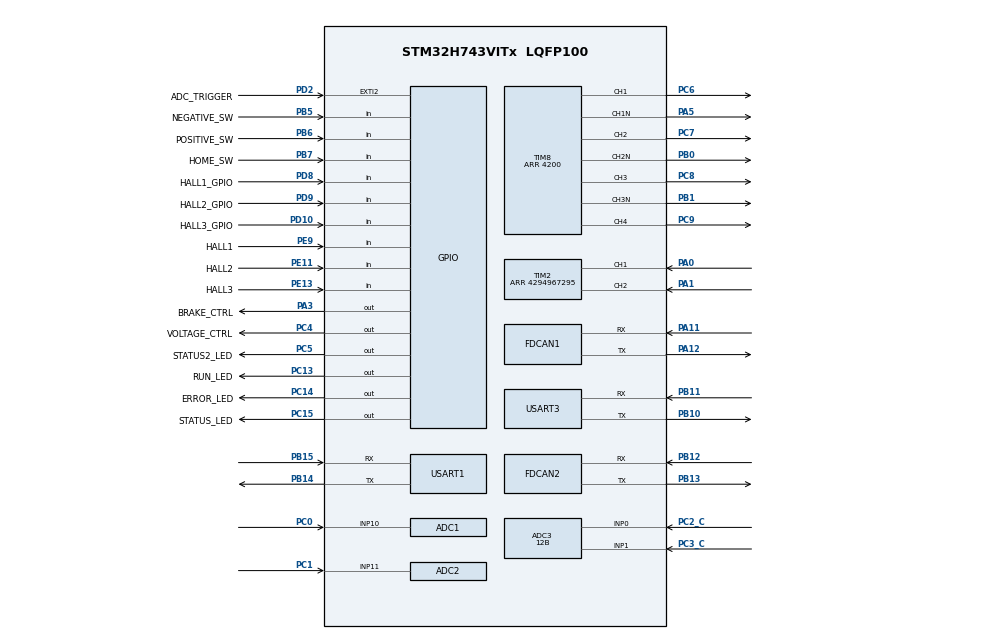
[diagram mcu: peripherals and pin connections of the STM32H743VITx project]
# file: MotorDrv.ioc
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ADC1.Channel-2\#ChannelRegularConversion=ADC_CHANNEL_10
ADC1.ClockPrescaler=ADC_CLOCK_ASYNC_DIV8
ADC1.ContinuousConvMode=DISABLE
ADC1.EOCSelection=ADC_EOC_SINGLE_CONV
ADC1.EnableRegularConversion=ENABLE
ADC1.ExternalTrigConv=ADC_EXTERNALTRIG_T8_TRGO
ADC1.ExternalTrigConvEdge=ADC_EXTERNALTRIGCONVEDGE_FALLING
ADC1.Mode=ADC_MODE_INDEPENDENT
ADC1.NbrOfConversion=1
ADC1.NbrOfConversionFlag=1
ADC1.OffsetNumber-2\#ChannelRegularConversion=ADC_OFFSET_NONE
ADC1.Rank-2\#ChannelRegularConversion=1
ADC1.Resolution=ADC_RESOLUTION_12B
ADC1.SamplingTime-2\#ChannelRegularConversion=ADC_SAMPLETIME_16CYCLES_5
ADC1.master=1
ADC2.Channel-2\#ChannelRegularConversion=ADC_CHANNEL_11
ADC2.ClockPrescaler=ADC_CLOCK_ASYNC_DIV8
ADC2.ConversionDataManagement=ADC_CONVERSIONDATA_DR
ADC2.EOCSelection=ADC_EOC_SINGLE_CONV
ADC2.ExternalTrigConv=ADC_EXTERNALTRIG_T8_TRGO
ADC2.ExternalTrigConvEdge=ADC_EXTERNALTRIGCONVEDGE_FALLING
ADC2.NbrOfConversionFlag=1
ADC2.OffsetNumber-2\#ChannelRegularConversion=ADC_OFFSET_NONE
ADC2.Rank-2\#ChannelRegularConversion=1
ADC2.Resolution=ADC_RESOLUTION_12B
ADC2.SamplingTime-2\#ChannelRegularConversion=ADC_SAMPLETIME_16CYCLES_5
ADC3.Channel-10\#ChannelRegularConversion=ADC_CHANNEL_TEMPSENSOR
ADC3.Channel-7\#ChannelRegularConversion=ADC_CHANNEL_0
ADC3.Channel-8\#ChannelRegularConversion=ADC_CHANNEL_1
ADC3.ClockPrescaler=ADC_CLOCK_ASYNC_DIV8
ADC3.ContinuousConvMode=DISABLE
ADC3.ConversionDataManagement=ADC_CONVERSIONDATA_DMA_CIRCULAR
ADC3.EOCSelection=ADC_EOC_SINGLE_CONV
ADC3.EnableRegularConversion=ENABLE
ADC3.ExternalTrigConv=ADC_EXTERNALTRIG_T8_TRGO
ADC3.ExternalTrigConvEdge=ADC_EXTERNALTRIGCONVEDGE_FALLING
ADC3.NbrOfConversion=3
ADC3.NbrOfConversionFlag=1
ADC3.OffsetNumber-10\#ChannelRegularConversion=ADC_OFFSET_NONE
ADC3.OffsetNumber-7\#ChannelRegularConversion=ADC_OFFSET_NONE
ADC3.OffsetNumber-8\#ChannelRegularConversion=ADC_OFFSET_NONE
ADC3.Overrun=ADC_OVR_DATA_PRESERVED
ADC3.Rank-10\#ChannelRegularConversion=3
ADC3.Rank-7\#ChannelRegularConversion=1
ADC3.Rank-8\#ChannelRegularConversion=2
ADC3.Resolution=ADC_RESOLUTION_12B
ADC3.SamplingTime-10\#ChannelRegularConversion=ADC_SAMPLETIME_16CYCLES_5
ADC3.SamplingTime-7\#ChannelRegularConversion=ADC_SAMPLETIME_16CYCLES_5
ADC3.SamplingTime-8\#ChannelRegularConversion=ADC_SAMPLETIME_2CYCLES_5
CORTEX_M7.CPU_DCache=Enabled
CORTEX_M7.CPU_ICache=Enabled
Dma.ADC3.2.Direction=DMA_PERIPH_TO_MEMORY
Dma.ADC3.2.EventEnable=DISABLE
Dma.ADC3.2.FIFOMode=DMA_FIFOMODE_DISABLE
Dma.ADC3.2.Instance=DMA1_Stream1
Dma.ADC3.2.MemDataAlignment=DMA_MDATAALIGN_HALFWORD
Dma.ADC3.2.MemInc=DMA_MINC_ENABLE
Dma.ADC3.2.Mode=DMA_CIRCULAR
Dma.ADC3.2.PeriphDataAlignment=DMA_PDATAALIGN_HALFWORD
Dma.ADC3.2.PeriphInc=DMA_PINC_DISABLE
Dma.ADC3.2.Polarity=HAL_DMAMUX_REQ_GEN_RISING
Dma.ADC3.2.Priority=DMA_PRIORITY_LOW
Dma.ADC3.2.RequestNumber=1
Dma.ADC3.2.SignalID=HAL_DMAMUX2_REQ_GEN_EXTI2
Dma.ADC3.2.SyncEnable=DISABLE
Dma.ADC3.2.SyncPolarity=HAL_DMAMUX_SYNC_NO_EVENT
Dma.ADC3.2.SyncRequestNumber=1
Dma.ADC3.2.SyncSignalID=NONE
Dma.Request0=USART1_RX
Dma.Request1=USART3_RX
Dma.Request2=ADC3
Dma.USART1_RX.0.Direction=DMA_PERIPH_TO_MEMORY
Dma.USART1_RX.0.EventEnable=DISABLE
Dma.USART1_RX.0.FIFOMode=DMA_FIFOMODE_ENABLE
Dma.USART1_RX.0.FIFOThreshold=DMA_FIFO_THRESHOLD_1QUARTERFULL
Dma.USART1_RX.0.Instance=DMA1_Stream2
Dma.USART1_RX.0.MemBurst=DMA_MBURST_SINGLE
Dma.USART1_RX.0.MemDataAlignment=DMA_MDATAALIGN_BYTE
Dma.USART1_RX.0.MemInc=DMA_MINC_ENABLE
Dma.USART1_RX.0.Mode=DMA_CIRCULAR
Dma.USART1_RX.0.PeriphBurst=DMA_PBURST_SINGLE
Dma.USART1_RX.0.PeriphDataAlignment=DMA_PDATAALIGN_BYTE
Dma.USART1_RX.0.PeriphInc=DMA_PINC_DISABLE
Dma.USART1_RX.0.Polarity=HAL_DMAMUX_REQ_GEN_RISING
Dma.USART1_RX.0.Priority=DMA_PRIORITY_LOW
Dma.USART1_RX.0.RequestNumber=1
Dma.USART1_RX.0.SignalID=HAL_DMAMUX1_REQ_GEN_DMAMUX1_CH1_EVT
Dma.USART1_RX.0.SyncEnable=DISABLE
Dma.USART1_RX.0.SyncPolarity=HAL_DMAMUX_SYNC_NO_EVENT
Dma.USART1_RX.0.SyncRequestNumber=1
Dma.USART1_RX.0.SyncSignalID=NONE
Dma.USART3_RX.1.Direction=DMA_PERIPH_TO_MEMORY
Dma.USART3_RX.1.EventEnable=DISABLE
Dma.USART3_RX.1.FIFOMode=DMA_FIFOMODE_ENABLE
Dma.USART3_RX.1.FIFOThreshold=DMA_FIFO_THRESHOLD_1QUARTERFULL
Dma.USART3_RX.1.Instance=DMA1_Stream0
Dma.USART3_RX.1.MemBurst=DMA_MBURST_SINGLE
Dma.USART3_RX.1.MemDataAlignment=DMA_MDATAALIGN_BYTE
Dma.USART3_RX.1.MemInc=DMA_MINC_ENABLE
Dma.USART3_RX.1.Mode=DMA_CIRCULAR
Dma.USART3_RX.1.PeriphBurst=DMA_PBURST_SINGLE
Dma.USART3_RX.1.PeriphDataAlignment=DMA_PDATAALIGN_BYTE
Dma.USART3_RX.1.PeriphInc=DMA_PINC_DISABLE
Dma.USART3_RX.1.Polarity=HAL_DMAMUX_REQ_GEN_RISING
Dma.USART3_RX.1.Priority=DMA_PRIORITY_LOW
Dma.USART3_RX.1.RequestNumber=1
Dma.USART3_RX.1.SignalID=HAL_DMAMUX1_REQ_GEN_DMAMUX1_CH2_EVT
Dma.USART3_RX.1.SyncEnable=DISABLE
Dma.USART3_RX.1.SyncPolarity=HAL_DMAMUX_SYNC_NO_EVENT
Dma.USART3_RX.1.SyncRequestNumber=1
Dma.USART3_RX.1.SyncSignalID=NONE
FDCAN1.DataPrescaler=1
FDCAN1.DataSyncJumpWidth=8
FDCAN1.DataTimeSeg1=3
FDCAN1.DataTimeSeg2=4
FDCAN1.NominalPrescaler=1
FDCAN1.NominalSyncJumpWidth=8
FDCAN1.NominalTimeSeg1=3
FDCAN1.NominalTimeSeg2=4
FDCAN1.RxBuffersNbr=0
FDCAN1.RxFifo0ElmtsNbr=1
FDCAN1.StdFiltersNbr=1
FDCAN1.TxBuffersNbr=0
FDCAN1.TxFifoQueueElmtsNbr=4
FDCAN2.DataSyncJumpWidth=4
FDCAN2.DataTimeSeg1=4
FDCAN2.DataTimeSeg2=3
FDCAN2.FrameFormat=FDCAN_FRAME_FD_BRS
FDCAN2.NominalSyncJumpWidth=8
FDCAN2.NominalTimeSeg1=39
FDCAN2.NominalTimeSeg2=8
FDCAN2.RxBufferSize=FDCAN_DATA_BYTES_64
FDCAN2.RxFifo0ElmtSize=FDCAN_DATA_BYTES_64
FDCAN2.RxFifo1ElmtSize=FDCAN_DATA_BYTES_64
FDCAN2.TxElmtSize=FDCAN_DATA_BYTES_64
Mcu.Family=STM32H7
Mcu.Name=STM32H743VITx
Mcu.Package=LQFP100
NVIC.ADC3_IRQn=true\:0\:0\:false\:false\:true\:true\:true
NVIC.ADC_IRQn=true\:0\:0\:false\:false\:true\:true\:true
NVIC.DMA1_Stream0_IRQn=true\:0\:0\:false\:false\:true\:false\:true
NVIC.DMA1_Stream1_IRQn=true\:2\:0\:true\:false\:true\:false\:true
NVIC.DMA1_Stream2_IRQn=true\:2\:0\:true\:false\:true\:false\:true
NVIC.EXTI2_IRQn=true\:0\:0\:false\:false\:true\:true\:true
NVIC.FDCAN1_IT0_IRQn=true\:2\:0\:true\:false\:true\:true\:true
NVIC.FDCAN2_IT0_IRQn=true\:2\:0\:true\:false\:true\:true\:true
NVIC.PriorityGroup=NVIC_PRIORITYGROUP_4
PA0.Signal=S_TIM2_CH1
PA1.Signal=S_TIM2_CH2
PA11.GPIO_PuPd=GPIO_PULLUP
PA11.GPIO_Speed=GPIO_SPEED_FREQ_VERY_HIGH
PA11.Mode=FDCANMaster
PA11.Signal=FDCAN1_RX
PA12.GPIO_PuPd=GPIO_PULLUP
PA12.GPIO_Speed=GPIO_SPEED_FREQ_VERY_HIGH
PA12.Mode=FDCANMaster
PA12.Signal=FDCAN1_TX
PA2.Signal=S_TIM2_CH3
PA3.GPIO_Label=BRAKE_CTRL
PA3.GPIO_ModeDefaultOutputPP=GPIO_MODE_OUTPUT_PP
PA3.GPIO_PuPd=GPIO_PULLDOWN
PA3.GPIO_Speed=GPIO_SPEED_FREQ_VERY_HIGH
PA3.PinState=GPIO_PIN_RESET
PA3.Signal=GPIO_Output
PA5.GPIO_PuPd=GPIO_PULLDOWN
PA5.GPIO_Speed=GPIO_SPEED_FREQ_VERY_HIGH
PA5.Mode=PWM Generation1 CH1 CH1N
PA5.Signal=TIM8_CH1N
PB0.GPIO_PuPd=GPIO_PULLDOWN
PB0.GPIO_Speed=GPIO_SPEED_FREQ_VERY_HIGH
PB0.Mode=PWM Generation2 CH2 CH2N
PB0.Signal=TIM8_CH2N
PB1.GPIO_PuPd=GPIO_PULLDOWN
PB1.GPIO_Speed=GPIO_SPEED_FREQ_VERY_HIGH
PB1.Mode=PWM Generation3 CH3 CH3N
PB1.Signal=TIM8_CH3N
PB10.GPIO_Speed=GPIO_SPEED_FREQ_VERY_HIGH
PB10.Mode=Asynchronous
PB10.Signal=USART3_TX
PB11.GPIO_Speed=GPIO_SPEED_FREQ_VERY_HIGH
PB11.Mode=Asynchronous
PB11.Signal=USART3_RX
PB12.GPIO_PuPd=GPIO_PULLUP
PB12.GPIO_Speed=GPIO_SPEED_FREQ_VERY_HIGH
PB12.Mode=FDCANFD
PB12.Signal=FDCAN2_RX
PB13.GPIO_PuPd=GPIO_PULLUP
PB13.GPIO_Speed=GPIO_SPEED_FREQ_VERY_HIGH
PB13.Mode=FDCANFD
PB13.Signal=FDCAN2_TX
PB14.Mode=Asynchronous
PB14.Signal=USART1_TX
PB15.Mode=Asynchronous
PB15.Signal=USART1_RX
PB5.GPIO_Label=NEGATIVE_SW
PB5.GPIO_Mode=GPIO_MODE_INPUT
PB5.GPIO_PuPd=GPIO_PULLDOWN
PB5.Signal=GPIO_Input
PB6.GPIO_Label=POSITIVE_SW
PB6.GPIO_Mode=GPIO_MODE_INPUT
PB6.GPIO_PuPd=GPIO_PULLDOWN
PB6.Signal=GPIO_Input
PB7.GPIO_Label=HOME_SW
PB7.GPIO_Mode=GPIO_MODE_INPUT
PB7.GPIO_PuPd=GPIO_PULLDOWN
PB7.Signal=GPIO_Input
PC0.Signal=ADCx_INP10
PC1.Signal=ADCx_INP11
PC13.GPIO_Label=RUN_LED
PC13.GPIO_ModeDefaultOutputPP=GPIO_MODE_OUTPUT_PP
PC13.GPIO_PuPd=GPIO_NOPULL
PC13.GPIO_Speed=GPIO_SPEED_FREQ_LOW
PC13.PinState=GPIO_PIN_RESET
PC13.Signal=GPIO_Output
PC14-OSC32_IN\ (OSC32_IN).GPIO_Label=ERROR_LED
PC14-OSC32_IN\ (OSC32_IN).GPIO_ModeDefaultOutputPP=GPIO_MODE_OUTPUT_PP
PC14-OSC32_IN\ (OSC32_IN).GPIO_PuPd=GPIO_NOPULL
PC14-OSC32_IN\ (OSC32_IN).GPIO_Speed=GPIO_SPEED_FREQ_LOW
PC14-OSC32_IN\ (OSC32_IN).PinState=GPIO_PIN_RESET
PC14-OSC32_IN\ (OSC32_IN).Signal=GPIO_Output
PC15-OSC32_OUT\ (OSC32_OUT).GPIO_Label=STATUS_LED
PC15-OSC32_OUT\ (OSC32_OUT).GPIO_ModeDefaultOutputPP=GPIO_MODE_OUTPUT_PP
PC15-OSC32_OUT\ (OSC32_OUT).GPIO_PuPd=GPIO_NOPULL
PC15-OSC32_OUT\ (OSC32_OUT).GPIO_Speed=GPIO_SPEED_FREQ_LOW
PC15-OSC32_OUT\ (OSC32_OUT).PinState=GPIO_PIN_RESET
PC15-OSC32_OUT\ (OSC32_OUT).Signal=GPIO_Output
PC2_C.Mode=IN0-Single-Ended
PC2_C.Signal=ADC3_INP0
PC3_C.Mode=IN1-Single-Ended
PC3_C.Signal=ADC3_INP1
PC4.GPIO_Label=VOLTAGE_CTRL
PC4.GPIO_ModeDefaultOutputPP=GPIO_MODE_OUTPUT_PP
PC4.GPIO_PuPd=GPIO_PULLDOWN
PC4.GPIO_Speed=GPIO_SPEED_FREQ_VERY_HIGH
PC4.PinState=GPIO_PIN_RESET
PC4.Signal=GPIO_Output
PC5.GPIO_Label=STATUS2_LED
PC5.GPIO_ModeDefaultOutputPP=GPIO_MODE_OUTPUT_PP
PC5.GPIO_PuPd=GPIO_NOPULL
PC5.GPIO_Speed=GPIO_SPEED_FREQ_LOW
PC5.PinState=GPIO_PIN_RESET
PC5.Signal=GPIO_Output
PC6.GPIO_PuPd=GPIO_PULLDOWN
PC6.GPIO_Speed=GPIO_SPEED_FREQ_VERY_HIGH
PC6.Signal=S_TIM8_CH1
PC7.GPIO_PuPd=GPIO_PULLDOWN
PC7.GPIO_Speed=GPIO_SPEED_FREQ_VERY_HIGH
PC7.Signal=S_TIM8_CH2
PC8.GPIO_PuPd=GPIO_PULLDOWN
PC8.GPIO_Speed=GPIO_SPEED_FREQ_VERY_HIGH
PC8.Signal=S_TIM8_CH3
PC9.GPIO_PuPd=GPIO_PULLDOWN
PC9.GPIO_Speed=GPIO_SPEED_FREQ_VERY_HIGH
PC9.Signal=S_TIM8_CH4
PD10.GPIO_Label=HALL3_GPIO
PD10.GPIO_Mode=GPIO_MODE_INPUT
PD10.GPIO_PuPd=GPIO_NOPULL
PD10.Signal=GPIO_Input
PD2.GPIO_Label=ADC_TRIGGER
PD2.GPIO_PuPd=GPIO_PULLDOWN
PD2.Signal=GPXTI2
PD8.GPIO_Label=HALL1_GPIO
PD8.GPIO_Mode=GPIO_MODE_INPUT
PD8.GPIO_PuPd=GPIO_NOPULL
PD8.Signal=GPIO_Input
PD9.GPIO_Label=HALL2_GPIO
PD9.GPIO_Mode=GPIO_MODE_INPUT
PD9.GPIO_PuPd=GPIO_NOPULL
PD9.Signal=GPIO_Input
PE11.GPIO_Label=HALL2
PE11.Signal=GPIO_Input
PE13.GPIO_Label=HALL3
PE13.Signal=GPIO_Input
PE9.GPIO_Label=HALL1
PE9.Signal=GPIO_Input
PH0-OSC_IN\ (PH0).Mode=HSE-External-Oscillator
PH0-OSC_IN\ (PH0).Signal=RCC_OSC_IN
PH1-OSC_OUT\ (PH1).Mode=HSE-External-Oscillator
PH1-OSC_OUT\ (PH1).Signal=RCC_OSC_OUT
ProjectManager.HeapSize=0x2000
ProjectManager.StackSize=0x2000
ProjectManager.TargetToolchain=EWARM V8
RCC.ADCCLockSelection=RCC_ADCCLKSOURCE_PLL3
RCC.ADCFreq_Value=84000000
RCC.APB1Freq_Value=84000000
RCC.APB2Freq_Value=84000000
RCC.APB3Freq_Value=84000000
RCC.APB4Freq_Value=84000000
RCC.CortexFreq_Value=168000000
RCC.D1CPRE=RCC_SYSCLK_DIV2
RCC.D1PPRE=RCC_APB3_DIV2
RCC.D2PPRE1=RCC_APB1_DIV2
RCC.D2PPRE2=RCC_APB2_DIV2
RCC.D3PPRE=RCC_APB4_DIV2
RCC.DIVM1=2
RCC.DIVM2=1
RCC.DIVM3=8
RCC.DIVN1=168
RCC.DIVN2=32
RCC.DIVN3=168
RCC.DIVP2=4
RCC.DIVQ1=4
RCC.DIVQ2=32
RCC.DIVR1=4
RCC.FDCANCLockSelection=RCC_FDCANCLKSOURCE_PLL2
RCC.HCLKFreq_Value=168000000
RCC.HSE_VALUE=8000000
RCC.PLLSourceVirtual=RCC_PLLSOURCE_HSE
RCC.PWR_Regulator_Voltage_Scale=PWR_REGULATOR_VOLTAGE_SCALE1
RCC.SYSCLKFreq_VALUE=336000000
RCC.SYSCLKSource=RCC_SYSCLKSOURCE_PLLCLK
RCC.USBFreq_Value=168000000
SH.ADCx_INP10.0=ADC1_INP10,IN10-Single-Ended
SH.ADCx_INP11.0=ADC2_INP11,IN11-Single-Ended
SH.S_TIM2_CH1.0=TIM2_CH1,Encoder_Interface
SH.S_TIM2_CH2.0=TIM2_CH2,Encoder_Interface
SH.S_TIM2_CH3.0=TIM2_CH3
SH.S_TIM8_CH1.0=TIM8_CH1,PWM Generation1 CH1 CH1N
SH.S_TIM8_CH2.0=TIM8_CH2,PWM Generation2 CH2 CH2N
SH.S_TIM8_CH3.0=TIM8_CH3,PWM Generation3 CH3 CH3N
SH.S_TIM8_CH4.0=TIM8_CH4,Output Compare4 CH4
TIM2.EncoderMode=TIM_ENCODERMODE_TI12
TIM2.Period=4294967295
TIM8.Break2State=TIM_BREAK2_DISABLE
TIM8.BreakPolarity=TIM_BREAKPOLARITY_HIGH
TIM8.BreakState=TIM_BREAK_DISABLE
TIM8.Channel-Output\ Compare4\ CH4=TIM_CHANNEL_4
TIM8.Channel-PWM\ Generation1\ CH1\ CH1N=TIM_CHANNEL_1
TIM8.Channel-PWM\ Generation2\ CH2\ CH2N=TIM_CHANNEL_2
TIM8.Channel-PWM\ Generation3\ CH3\ CH3N=TIM_CHANNEL_3
TIM8.CounterMode=TIM_COUNTERMODE_CENTERALIGNED1
TIM8.DeadTime=84
TIM8.OCMode_4=TIM_OCMODE_TOGGLE
TIM8.OCMode_PWM-PWM\ Generation1\ CH1\ CH1N=TIM_OCMODE_PWM2
TIM8.OCMode_PWM-PWM\ Generation2\ CH2\ CH2N=TIM_OCMODE_PWM2
TIM8.OCMode_PWM-PWM\ Generation3\ CH3\ CH3N=TIM_OCMODE_PWM2
TIM8.OffStateRunMode=TIM_OSSR_DISABLE
TIM8.Period=4200
TIM8.Pulse-Output\ Compare4\ CH4=4158
TIM8.Pulse-PWM\ Generation1\ CH1\ CH1N=4200
TIM8.Pulse-PWM\ Generation2\ CH2\ CH2N=4200
TIM8.Pulse-PWM\ Generation3\ CH3\ CH3N=4200
TIM8.SourceBRK2DigInput=TIM_BREAKINPUTSOURCE_DISABLE
TIM8.SourceBRKDigInput=TIM_BREAKINPUTSOURCE_DISABLE
TIM8.TIM_MasterOutputTrigger=TIM_TRGO_OC4REF
TIM8.TIM_MasterOutputTrigger2=TIM_TRGO2_OC4REF
USART1.VirtualMode-Asynchronous=VM_ASYNC
USART3.VirtualMode-Asynchronous=VM_ASYNC
VP_ADC3_TempSens_Input.Mode=IN-TempSens
VP_TIM8_VS_ClockSourceINT.Mode=Internal
board=custom

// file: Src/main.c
/* USER CODE BEGIN Header */
/**
  ******************************************************************************
  * @file           : main.c
  * @brief          : Main program body
  ******************************************************************************
  ** This notice applies to any and all portions of this file
  * that are not between comment pairs USER CODE BEGIN and
  * USER CODE END. Other portions of this file, whether
  * inserted by the user or by software development tools
  * are owned by their respective copyright owners.
  *
  * COPYRIGHT(c) 2019 STMicroelectronics
  *
  * Redistribution and use in source and binary forms, with or without modification,
  * are permitted provided that the following conditions are met:
  *   1. Redistributions of source code must retain the above copyright notice,
  *      this list of conditions and the following disclaimer.
  *   2. Redistributions in binary form must reproduce the above copyright notice,
  *      this list of conditions and the following disclaimer in the documentation
  *      and/or other materials provided with the distribution.
  *   3. Neither the name of STMicroelectronics nor the names of its contributors
  *      may be used to endorse or promote products derived from this software
  *      without specific prior written permission.
  *
  * THIS SOFTWARE IS PROVIDED BY THE COPYRIGHT HOLDERS AND CONTRIBUTORS "AS IS"
  * AND ANY EXPRESS OR IMPLIED WARRANTIES, INCLUDING, BUT NOT LIMITED TO, THE
  * IMPLIED WARRANTIES OF MERCHANTABILITY AND FITNESS FOR A PARTICULAR PURPOSE ARE
  * DISCLAIMED. IN NO EVENT SHALL THE COPYRIGHT HOLDER OR CONTRIBUTORS BE LIABLE
  * FOR ANY DIRECT, INDIRECT, INCIDENTAL, SPECIAL, EXEMPLARY, OR CONSEQUENTIAL
  * DAMAGES (INCLUDING, BUT NOT LIMITED TO, PROCUREMENT OF SUBSTITUTE GOODS OR
  * SERVICES; LOSS OF USE, DATA, OR PROFITS; OR BUSINESS INTERRUPTION) HOWEVER
  * CAUSED AND ON ANY THEORY OF LIABILITY, WHETHER IN CONTRACT, STRICT LIABILITY,
  * OR TORT (INCLUDING NEGLIGENCE OR OTHERWISE) ARISING IN ANY WAY OUT OF THE USE
  * OF THIS SOFTWARE, EVEN IF ADVISED OF THE POSSIBILITY OF SUCH DAMAGE.
  *
  ******************************************************************************
  */
/* USER CODE END Header */

#include "main.h"

/* USER CODE BEGIN Includes */
#include "ServoControllerInterface.h"
#include "string.h"
#include "can_comm.h"

/* USER CODE END Includes */

/* USER CODE BEGIN PD */
#define SERVO_FUNC_USE
#define ADC_USE_DMA
//https://community.st.com/s/article/FAQ-DMA-is-not-working-on-STM32H7-devices
#ifdef ADC_USE_DMA
#define ADC3_CHANNEL_NUM						3
#else
#define ADC3_CHANNEL_NUM						3
#endif

/* USER CODE END PD */

ADC_HandleTypeDef hadc1;
ADC_HandleTypeDef hadc2;
ADC_HandleTypeDef hadc3;
DMA_HandleTypeDef hdma_adc3;

FDCAN_HandleTypeDef hfdcan1;
FDCAN_HandleTypeDef hfdcan2;

TIM_HandleTypeDef htim2;
TIM_HandleTypeDef htim8;

UART_HandleTypeDef huart1;
UART_HandleTypeDef huart3;
DMA_HandleTypeDef hdma_usart1_rx;
DMA_HandleTypeDef hdma_usart3_rx;

/* USER CODE BEGIN PV */
//FDCAN_FilterTypeDef sFilterConfig;
FDCAN_RxHeaderTypeDef RxHeader[2];
uint8_t RxData[2][16];
FDCAN_TxHeaderTypeDef TxHeader[2];
uint8_t TxData[2][16];
//uint8_t TxData2[] = {0x10, 0x32, 0x54, 0x76, 0x98, 0x00, 0x11, 0x22, 0x33, 0x44, 0x55, 0x66, 0x77, 0x88, 0x99, 0x00};
//FDCAN_FilterTypeDef sFilterConfig;
int fifo0TxNum;

uint8_t gRunCurrentController = 0;
uint32_t nRunLed = 0;
uint16_t nRunLedCnt; //pjg++190509
uint32_t nExt2Irq = 0;
uint32_t nAdcIrq = 0;
uint32_t nAdc2Irq = 0;
uint32_t nDma2Irq = 0;

int16_t adc12Result[2];
#ifdef ADC_USE_DMA
/* Variable containing ADC conversions results */
//static int16_t   adc3Result[ADC3_CHANNEL_NUM];
uint16_t adc3Result[ADC3_CHANNEL_NUM] __attribute__((section(".ARM.__at_0x24000010")));
#else
int16_t adc3Result[ADC3_CHANNEL_NUM];
#endif
int32_t encoderPulse = 0;
volatile uint8_t hallSensorStatus = 0x00;
uint8_t encoder1Type = 0;
uint8_t encoder2Type = 0;
uint16_t nStatus2Led = 0;

/* USER CODE END PV */

void SystemClock_Config(void);
static void MX_GPIO_Init(void);
static void MX_DMA_Init(void);
static void MX_TIM8_Init(void);
static void MX_FDCAN1_Init(void);
static void MX_FDCAN2_Init(void);
static void MX_TIM2_Init(void);
static void MX_ADC1_Init(void);
static void MX_ADC2_Init(void);
static void MX_ADC3_Init(void);
static void MX_USART3_UART_Init(void);
static void MX_USART1_UART_Init(void);

/* USER CODE BEGIN 0 */
void HAL_UART_RxCpltCallback(UART_HandleTypeDef * huart)
{
	if (huart->Instance == USART1) {	//debug
		//HAL_UART_Receive_DMA(huart, (uint8_t *)&uartRxData[0], 1);
	}
	else if (huart->Instance == USART2) {	//remocon
		//CTouchDrv_PutData(uartRxData[1]);
		//HAL_UART_Receive_DMA(huart, (uint8_t *)&uartRxData[1], 1);
	}
	else if (huart->Instance == USART3) {	//WiFI
		//HAL_UART_Receive_DMA(huart, (uint8_t *)&uartRxData[2], 1);
	}
	else if (huart->Instance == USART6) {	//IMU
		//HAL_UART_Receive_DMA(huart, (uint8_t *)&uartRxData[3], 1);
	}
}

/**
  * @brief  Conversion complete callback in non-blocking mode
  * @param  hadc: ADC handle
  * @retval None
  */
void HAL_ADC_ConvCpltCallback(ADC_HandleTypeDef* hadc)
{
	//uint32_t i;
	if (hadc->Instance == ADC1 || hadc->Instance == ADC2) {
		#ifdef SERVO_FUNC_USE
		adc12Result[0] = (int16_t)HAL_ADC_GetValue(&hadc1); //U current
		adc12Result[1] = (int16_t)HAL_ADC_GetValue(&hadc2); //V current

		RunCurrentController(adc12Result[0], adc12Result[1]);

		if(++gRunCurrentController >= 10) {
			CalculateVelocity(encoderPulse);
			CalculateLoadTorque();
			RunVelocityPositionController();
			gRunCurrentController = 0;
		}
		#endif
		nAdcIrq++;
		if (nAdcIrq > nRunLedCnt)
		{
			RUN_LED_TOGGLE;
			nAdcIrq = 0;
		}
	}
	else if (hadc->Instance == ADC3) {
		#ifdef SERVO_FUNC_USE
		#ifdef ADC_USE_DMA
		#else
		adc3Result[0] = (int16_t)HAL_ADC_GetValue(&hadc3);//voltage
		adc3Result[1] = (int16_t)HAL_ADC_GetValue(&hadc3); //temp
		adc3Result[2] = (int16_t)HAL_ADC_GetValue(&hadc3); //mcu temp
		#endif
		CalculateVoltageTemperature(adc3Result[0], adc3Result[1]);
		//RUN_LED_TOGGLE;
		#endif
	}
}

/**
  * @brief  Conversion DMA half-transfer callback in non-blocking mode
  * @param  hadc: ADC handle
  * @retval None
  */
#if 0
void HAL_ADC_ConvHalfCpltCallback(ADC_HandleTypeDef* hadc)
{
	if (hadc->Instance == ADC3) {
		#ifdef SERVO_FUNC_USE
		//CalculateVoltageTemperature(adc3Result[0], adc3Result[1]);
		#endif
	}
	/* Invalidate Data Cache to get the updated content of the SRAM on the first half of the ADC converted data buffer: 32 bytes */
	//SCB_InvalidateDCache_by_Addr((uint32_t *) &aADCxConvertedData[0], ADC_CONVERTED_DATA_BUFFER_SIZE);
}
#endif

//오버런(overrun)이 발생하면 ADC 트리거를 다시 주기 위한 함수입니다.
void HAL_ADC_ErrorCallback(ADC_HandleTypeDef *hadc)
{
	//hadc->Instance->CR2 |= (uint32_t)ADC_CR2_SWSTART;
	//HAL_GPIO_TogglePin(GPIOC, STATUS2_LED_Pin);
}

 /**
  * @brief EXTI line detection callback
  * @param GPIO_Pin: Specifies the pins connected EXTI line
  * @retval None
  */
void HAL_GPIO_EXTI_Callback(uint16_t GPIO_Pin)
{
	uint8_t hallValue;

	//if (GPIO_Pin == GPIO_PIN_2)
	{
		//nExt2Irq++;
		//if (nExt2Irq > 1000) {
		//	HAL_GPIO_TogglePin(GPIOC, STATUS2_LED_Pin);
		//	nExt2Irq = 0;
		//}
		//RUN_LED_TOGGLE;
		#ifdef SERVO_FUNC_USE
		#if 1
		hallSensorStatus = 0;
		if (GPIOE->IDR & 0x200) hallSensorStatus = 0x1;
		if (GPIOE->IDR & 0x800) hallSensorStatus |= 0x2;
		if (GPIOE->IDR & 0x2000) hallSensorStatus |= 0x4;
		#else
		hallSensorStatus = (GPIOD->IDR >> 8) & 0x7;
		#endif
		encoderPulse = (int32_t)TIM2->CNT;
		CalculateElecAngle(hallSensorStatus, encoderPulse);
		#endif
	}
}

void HAL_FDCAN_RxFifo0Callback(FDCAN_HandleTypeDef *hfdcan, uint32_t RxFifo0ITs)
{
	uint32_t len;

	if((RxFifo0ITs & FDCAN_IT_RX_FIFO0_WATERMARK) != RESET)
	{
		if (hfdcan->Instance == FDCAN1) {
			/* Retreive Rx messages from RX FIFO0 */
			HAL_FDCAN_GetRxMessage(hfdcan, FDCAN_RX_FIFO0, &RxHeader[0], RxData[0]);
			#ifdef SERVO_FUNC_USE
			if(ProcessSdoCan(&RxHeader[0].Identifier, RxData[0], &len) >= 0) {
		                if (len > 8) len = 8;
				//memcpy(TxData[0], RxData[0], len);
				TxHeader[0].Identifier = RxHeader[0].Identifier;
				TxHeader[0].DataLength = (uint32_t)(len<<16);
				HAL_FDCAN_AddMessageToTxFifoQ(hfdcan, &TxHeader[0], RxData[0]);
				//if (TxData[0][1] == 0x41 && TxData[0][2] == 0x60) {
					if (nStatus2Led++ > 200) {
						nStatus2Led = 0;
						//STATUS2_LED_TOGGLE;
						HAL_GPIO_TogglePin(GPIOC, STATUS2_LED_Pin);
					}
				//}
			}
			while (Callback_MotorInfoSend(&RxHeader[0].Identifier, RxData[0], &RxHeader[0].DataLength)) { //pjg++180710
				//memcpy(TxData[0], RxData[0], len);
				TxHeader[0].Identifier = RxHeader[0].Identifier;
				TxHeader[0].DataLength = (uint32_t)(len<<16);
				HAL_FDCAN_AddMessageToTxFifoQ(hfdcan, &TxHeader[0], RxData[0]);
				if (nStatus2Led++ > 200) {
					nStatus2Led = 0;
					//STATUS2_LED_TOGGLE;
					HAL_GPIO_TogglePin(GPIOC, STATUS2_LED_Pin);
				}
			}
			#endif
			/* Activate Rx FIFO 0 watermark notification */
			HAL_FDCAN_ActivateNotification(hfdcan, FDCAN_IT_RX_FIFO0_WATERMARK, fifo0TxNum);
		}
		else if (hfdcan->Instance == FDCAN2) {
			/* Retreive Rx messages from RX FIFO0 */
			HAL_FDCAN_GetRxMessage(hfdcan, FDCAN_RX_FIFO0, &RxHeader[1], RxData[1]);
			/* Activate Rx FIFO 0 watermark notification */
			HAL_FDCAN_ActivateNotification(hfdcan, FDCAN_IT_RX_FIFO0_WATERMARK, 0);
		}
	}
}

void FDCAN1_Setting(void)
{
	int fifo0RxNum;
	FDCAN_FilterTypeDef sFilterConfig;

	fifo0RxNum = 1;
	fifo0TxNum = 0;
	/*                Bit time configuration:
	Bit time parameter         | Nominal      |  Data
	---------------------------|--------------|----------------
	fdcan_ker_ck               | 20 MHz       | 20 MHz
	Time_quantum (tq)          | 50 ns        | 50 ns
	Synchronization_segment    | 1 tq         | 1 tq
	Propagation_segment        | 23 tq        | 1 tq
	Phase_segment_1            | 8 tq         | 4 tq
	Phase_segment_2            | 8 tq         | 4 tq
	Synchronization_Jump_width | 8 tq         | 4 tq
	Bit_length                 | 40 tq = 2 탎 | 10 tq = 0.5 탎
	Bit_rate                   | 0.5 MBit/s   | 2 MBit/s
	*/
	hfdcan1.Instance = FDCAN1;
	hfdcan1.Init.FrameFormat = FDCAN_FRAME_CLASSIC;//FDCAN_FRAME_FD_BRS;
	hfdcan1.Init.Mode = FDCAN_MODE_NORMAL;
	hfdcan1.Init.AutoRetransmission = ENABLE;
	hfdcan1.Init.TransmitPause = DISABLE;
	hfdcan1.Init.ProtocolException = ENABLE;
	hfdcan1.Init.NominalPrescaler = 0x1; /* tq = NominalPrescaler x (1/fdcan_ker_ck) */
	hfdcan1.Init.NominalSyncJumpWidth = 0x8;
	hfdcan1.Init.NominalTimeSeg1 = 0x3;//1F; /* NominalTimeSeg1 = Propagation_segment + Phase_segment_1 */
	hfdcan1.Init.NominalTimeSeg2 = 0x4;//8;
	hfdcan1.Init.DataPrescaler = 0x1;//1;
	hfdcan1.Init.DataSyncJumpWidth = 0x8;//4;
	hfdcan1.Init.DataTimeSeg1 = 0x3;//1F;//5; /* DataTimeSeg1 = Propagation_segment + Phase_segment_1 */
	hfdcan1.Init.DataTimeSeg2 = 0x4;//4;
	hfdcan1.Init.MessageRAMOffset = 0;
	hfdcan1.Init.StdFiltersNbr = 1;
	hfdcan1.Init.ExtFiltersNbr = 0;
	hfdcan1.Init.RxFifo0ElmtsNbr = fifo0RxNum;
	hfdcan1.Init.RxFifo0ElmtSize = FDCAN_DATA_BYTES_8;
	hfdcan1.Init.RxFifo1ElmtsNbr = 0;
	hfdcan1.Init.RxBuffersNbr = 0;
	hfdcan1.Init.RxBufferSize = 0;//FDCAN_DATA_BYTES_8;
	hfdcan1.Init.TxEventsNbr = 0;
	hfdcan1.Init.TxBuffersNbr = fifo0TxNum;
	hfdcan1.Init.TxFifoQueueElmtsNbr = 1;
	hfdcan1.Init.TxFifoQueueMode = FDCAN_TX_FIFO_OPERATION;//FDCAN_TX_QUEUE_OPERATION;;
	hfdcan1.Init.TxElmtSize = FDCAN_DATA_BYTES_8;
	HAL_FDCAN_Init(&hfdcan1);

	/* Configure Rx filter */
	sFilterConfig.IdType = FDCAN_STANDARD_ID;
	sFilterConfig.FilterIndex = 0;
	sFilterConfig.FilterType = FDCAN_FILTER_MASK;
	sFilterConfig.FilterConfig = FDCAN_FILTER_TO_RXFIFO0;
	sFilterConfig.FilterID1 = 0;//0x111;
	sFilterConfig.FilterID2 = 0;//0x7FF; /* For acceptance, MessageID and FilterID1 must match exactly */
	HAL_FDCAN_ConfigFilter(&hfdcan1, &sFilterConfig);

	/* Configure Rx FIFO 0 watermark to 2 */
	HAL_FDCAN_ConfigFifoWatermark(&hfdcan1, FDCAN_CFG_RX_FIFO0, fifo0RxNum);

	/* Activate Rx FIFO 0 watermark notification */
	HAL_FDCAN_ActivateNotification(&hfdcan1, FDCAN_IT_RX_FIFO0_WATERMARK, fifo0TxNum);

	/* Prepare Tx Header */
	TxHeader[0].Identifier = 0x581;
	TxHeader[0].IdType = FDCAN_STANDARD_ID;
	TxHeader[0].TxFrameType = FDCAN_DATA_FRAME;
	TxHeader[0].DataLength = FDCAN_DLC_BYTES_8;
	TxHeader[0].ErrorStateIndicator = FDCAN_ESI_ACTIVE;//FDCAN_ESI_PASSIVE;//;
	TxHeader[0].BitRateSwitch = FDCAN_BRS_OFF;
	TxHeader[0].FDFormat = FDCAN_CLASSIC_CAN;
	TxHeader[0].TxEventFifoControl = FDCAN_NO_TX_EVENTS;
	TxHeader[0].MessageMarker = 0;

	/* Start the FDCAN module */
	HAL_FDCAN_Start(&hfdcan1);
}

void FDCAN2_Setting(void)
{
#if 1
	int fifo0Num;
	FDCAN_FilterTypeDef sFilterConfig;

	fifo0Num = 1;
	/*                Bit time configuration:
	Bit time parameter         | Nominal      |  Data
	---------------------------|--------------|----------------
	fdcan_ker_ck               | 20 MHz       | 20 MHz
	Time_quantum (tq)          | 50 ns        | 50 ns
	Synchronization_segment    | 1 tq         | 1 tq
	Propagation_segment        | 23 tq        | 1 tq
	Phase_segment_1            | 8 tq         | 4 tq
	Phase_segment_2            | 8 tq         | 4 tq
	Synchronization_Jump_width | 8 tq         | 4 tq
	Bit_length                 | 40 tq = 2 탎 | 10 tq = 0.5 탎
	Bit_rate                   | 0.5 MBit/s   | 2 MBit/s
	*/
	hfdcan2.Instance = FDCAN2;
	hfdcan2.Init.FrameFormat = FDCAN_FRAME_FD_BRS;
	hfdcan2.Init.Mode = FDCAN_MODE_NORMAL;
	hfdcan2.Init.AutoRetransmission = ENABLE;
	hfdcan2.Init.TransmitPause = DISABLE;
	hfdcan2.Init.ProtocolException = ENABLE;
	hfdcan2.Init.NominalPrescaler = 0x1; /* tq = NominalPrescaler x (1/fdcan_ker_ck) */
	hfdcan2.Init.NominalSyncJumpWidth = 0x8;
	hfdcan2.Init.NominalTimeSeg1 = 0x3; /* NominalTimeSeg1 = Propagation_segment + Phase_segment_1 */
	hfdcan2.Init.NominalTimeSeg2 = 0xC;
	hfdcan2.Init.DataPrescaler = 0x1;
	hfdcan2.Init.DataSyncJumpWidth = 0x8;
	hfdcan2.Init.DataTimeSeg1 = 0x2; /* DataTimeSeg1 = Propagation_segment + Phase_segment_1 */
	hfdcan2.Init.DataTimeSeg2 = 0x1;
	hfdcan2.Init.MessageRAMOffset = 0;
	hfdcan2.Init.StdFiltersNbr = 1;
	hfdcan2.Init.ExtFiltersNbr = 0;
	hfdcan2.Init.RxFifo0ElmtsNbr = fifo0Num;
	hfdcan2.Init.RxFifo0ElmtSize = FDCAN_DATA_BYTES_8;
	hfdcan2.Init.RxFifo1ElmtsNbr = 0;
	hfdcan2.Init.RxBuffersNbr = 0;
	hfdcan2.Init.TxEventsNbr = 0;
	hfdcan2.Init.TxBuffersNbr = fifo0TxNum;
	hfdcan2.Init.TxFifoQueueElmtsNbr = 1;
	hfdcan2.Init.TxFifoQueueMode = FDCAN_TX_FIFO_OPERATION;
	hfdcan2.Init.TxElmtSize = FDCAN_DATA_BYTES_8;
	HAL_FDCAN_Init(&hfdcan2);

	/* Configure Rx filter */
	sFilterConfig.IdType = FDCAN_STANDARD_ID;
	sFilterConfig.FilterIndex = 0;
	sFilterConfig.FilterType = FDCAN_FILTER_MASK;
	sFilterConfig.FilterConfig = FDCAN_FILTER_TO_RXFIFO0;
	sFilterConfig.FilterID1 = 0;//0x111;
	sFilterConfig.FilterID2 = 0;//0x7FF; /* For acceptance, MessageID and FilterID1 must match exactly */
	HAL_FDCAN_ConfigFilter(&hfdcan2, &sFilterConfig);

	/* Configure Rx FIFO 0 watermark to 2 */
	HAL_FDCAN_ConfigFifoWatermark(&hfdcan2, FDCAN_CFG_RX_FIFO0, fifo0Num);

	/* Activate Rx FIFO 0 watermark notification */
	HAL_FDCAN_ActivateNotification(&hfdcan2, FDCAN_IT_RX_FIFO0_WATERMARK, fifo0TxNum);

	/* Prepare Tx Header */
	TxHeader[0].Identifier = 0x581;//0x111;
	TxHeader[0].IdType = FDCAN_STANDARD_ID;
	TxHeader[0].TxFrameType = FDCAN_DATA_FRAME;
	TxHeader[0].DataLength = FDCAN_DLC_BYTES_8;
	TxHeader[0].ErrorStateIndicator = FDCAN_ESI_ACTIVE;
	TxHeader[0].BitRateSwitch = FDCAN_BRS_ON;
	TxHeader[0].FDFormat = FDCAN_FD_CAN;
	TxHeader[0].TxEventFifoControl = FDCAN_NO_TX_EVENTS;
	TxHeader[0].MessageMarker = 0;

	/* Start the FDCAN module */
	HAL_FDCAN_Start(&hfdcan2);
#else
	int fifo0RxNum;
	FDCAN_FilterTypeDef sFilterConfig;

	fifo0RxNum = 1;
	fifo0TxNum = 0;
	/*                Bit time configuration:
	Bit time parameter         | Nominal      |  Data
	---------------------------|--------------|----------------
	fdcan_ker_ck               | 20 MHz       | 20 MHz
	Time_quantum (tq)          | 50 ns        | 50 ns
	Synchronization_segment    | 1 tq         | 1 tq
	Propagation_segment        | 23 tq        | 1 tq
	Phase_segment_1            | 8 tq         | 4 tq
	Phase_segment_2            | 8 tq         | 4 tq
	Synchronization_Jump_width | 8 tq         | 4 tq
	Bit_length                 | 40 tq = 2 탎 | 10 tq = 0.5 탎
	Bit_rate                   | 0.5 MBit/s   | 2 MBit/s
	*/
	hfdcan2.Instance = FDCAN2;
	hfdcan2.Init.FrameFormat = FDCAN_FRAME_CLASSIC;//FDCAN_FRAME_FD_BRS;
	hfdcan2.Init.Mode = FDCAN_MODE_NORMAL;
	hfdcan2.Init.AutoRetransmission = ENABLE;
	hfdcan2.Init.TransmitPause = DISABLE;
	hfdcan2.Init.ProtocolException = ENABLE;
	hfdcan2.Init.NominalPrescaler = 0x1; /* tq = NominalPrescaler x (1/fdcan_ker_ck) */
	hfdcan2.Init.NominalSyncJumpWidth = 0x8;
	hfdcan2.Init.NominalTimeSeg1 = 0x3;//1F; /* NominalTimeSeg1 = Propagation_segment + Phase_segment_1 */
	hfdcan2.Init.NominalTimeSeg2 = 0x4;//8;
	hfdcan2.Init.DataPrescaler = 0x1;//1;
	hfdcan2.Init.DataSyncJumpWidth = 0x8;//4;
	hfdcan2.Init.DataTimeSeg1 = 0x3;//1F;//5; /* DataTimeSeg1 = Propagation_segment + Phase_segment_1 */
	hfdcan2.Init.DataTimeSeg2 = 0x4;//4;
	hfdcan2.Init.MessageRAMOffset = 0;
	hfdcan2.Init.StdFiltersNbr = 1;
	hfdcan2.Init.ExtFiltersNbr = 0;
	hfdcan2.Init.RxFifo0ElmtsNbr = fifo0RxNum;
	hfdcan2.Init.RxFifo0ElmtSize = FDCAN_DATA_BYTES_8;
	hfdcan2.Init.RxFifo1ElmtsNbr = 0;
	hfdcan2.Init.RxBuffersNbr = 0;
	hfdcan2.Init.RxBufferSize = 0;//FDCAN_DATA_BYTES_8;
	hfdcan2.Init.TxEventsNbr = 0;
	hfdcan2.Init.TxBuffersNbr = fifo0TxNum;
	hfdcan2.Init.TxFifoQueueElmtsNbr = 1;
	hfdcan2.Init.TxFifoQueueMode = FDCAN_TX_FIFO_OPERATION;//FDCAN_TX_QUEUE_OPERATION;;
	hfdcan2.Init.TxElmtSize = FDCAN_DATA_BYTES_8;
	HAL_FDCAN_Init(&hfdcan2);

	/* Configure Rx filter */
	sFilterConfig.IdType = FDCAN_STANDARD_ID;
	sFilterConfig.FilterIndex = 0;
	sFilterConfig.FilterType = FDCAN_FILTER_MASK;
	sFilterConfig.FilterConfig = FDCAN_FILTER_TO_RXFIFO0;
	sFilterConfig.FilterID1 = 0;//0x111;
	sFilterConfig.FilterID2 = 0;//0x7FF; /* For acceptance, MessageID and FilterID1 must match exactly */
	HAL_FDCAN_ConfigFilter(&hfdcan2, &sFilterConfig);

	/* Configure Rx FIFO 0 watermark to 2 */
	HAL_FDCAN_ConfigFifoWatermark(&hfdcan2, FDCAN_CFG_RX_FIFO0, fifo0RxNum);

	/* Activate Rx FIFO 0 watermark notification */
	HAL_FDCAN_ActivateNotification(&hfdcan2, FDCAN_IT_RX_FIFO0_WATERMARK, fifo0TxNum);

	/* Prepare Tx Header */
	TxHeader[0].Identifier = 0x581;
	TxHeader[0].IdType = FDCAN_STANDARD_ID;
	TxHeader[0].TxFrameType = FDCAN_DATA_FRAME;
	TxHeader[0].DataLength = FDCAN_DLC_BYTES_8;
	TxHeader[0].ErrorStateIndicator = FDCAN_ESI_ACTIVE;//FDCAN_ESI_PASSIVE;//;
	TxHeader[0].BitRateSwitch = FDCAN_BRS_OFF;
	TxHeader[0].FDFormat = FDCAN_CLASSIC_CAN;
	TxHeader[0].TxEventFifoControl = FDCAN_NO_TX_EVENTS;
	TxHeader[0].MessageMarker = 0;

	/* Start the FDCAN module */
	HAL_FDCAN_Start(&hfdcan2);
#endif
}

/**
  * @brief  Configure the MPU attributes as Write Through for Internal D1SRAM.
  * @note   The Base Address is 0x24000000 since this memory interface is the AXI.
  *         The Configured Region Size is 512KB because same as D1SRAM size.
  * @param  None
  * @retval None
  */
static void MPU_Config(void)
{
  MPU_Region_InitTypeDef MPU_InitStruct;

  /* Disable the MPU */
  HAL_MPU_Disable();

  /* Configure the MPU attributes as WT for SRAM */
  MPU_InitStruct.Enable = MPU_REGION_ENABLE;
  MPU_InitStruct.BaseAddress = 0x24000000;
  MPU_InitStruct.Size = MPU_REGION_SIZE_512KB;
  MPU_InitStruct.AccessPermission = MPU_REGION_FULL_ACCESS;
  MPU_InitStruct.IsBufferable = MPU_ACCESS_NOT_BUFFERABLE;
  MPU_InitStruct.IsCacheable = MPU_ACCESS_CACHEABLE;
  MPU_InitStruct.IsShareable = MPU_ACCESS_SHAREABLE;
  MPU_InitStruct.Number = MPU_REGION_NUMBER0;
  MPU_InitStruct.TypeExtField = MPU_TEX_LEVEL0;
  MPU_InitStruct.SubRegionDisable = 0x00;
  MPU_InitStruct.DisableExec = MPU_INSTRUCTION_ACCESS_ENABLE;

  HAL_MPU_ConfigRegion(&MPU_InitStruct);

  /* Enable the MPU */
  HAL_MPU_Enable(MPU_PRIVILEGED_DEFAULT);
}

/* USER CODE END 0 */

int main(void)
{
  /* USER CODE BEGIN 1 */
  /* Configure the MPU attributes as Write Through */
  MPU_Config();

  /* USER CODE END 1 */

  /* Enable I-Cache---------------------------------------------------------*/
  SCB_EnableICache();

  /* Enable D-Cache---------------------------------------------------------*/
  SCB_EnableDCache();

  /* MCU Configuration--------------------------------------------------------*/

  /* Reset of all peripherals, Initializes the Flash interface and the Systick. */
  HAL_Init();

  /* Configure the system clock */
  SystemClock_Config();

  /* Initialize all configured peripherals */
  MX_GPIO_Init();
  MX_DMA_Init();
  MX_TIM8_Init();
  MX_FDCAN1_Init();
  MX_FDCAN2_Init();
  MX_TIM2_Init();
  MX_ADC1_Init();
  MX_ADC2_Init();
  MX_ADC3_Init();
  MX_USART3_UART_Init();
  MX_USART1_UART_Init();
  /* USER CODE BEGIN 2 */
 	//	Servo Controller
	InitServoController();
	//LoadMotorProperty(MAXONMOTOR_EC60_FLAT_100W_408057); //rohau pedal motor
    	//LoadMotorProperty(CELERA_UTH_63_B18_Cx000); //1st 1dof test(170620)
    	//LoadMotorProperty(KOLLMORGEN_01810_C); //2nd 1dof test bed (180310)
	//LoadMotorProperty(MAXONMOTOR_ECI52_60W); //2nd goods (samsung-H4L):single leg AM_MF0095020
//	LoadMotorProperty(AM_MF0095020); //power gait robot(190318)
	LoadMotorProperty(MOTOR_ID_NONE);

	encoder1Type = GetEncoder1Type();
	encoder2Type = GetEncoder2Type();
#if 1
	//	PWM
	HAL_TIM_PWM_Start(&htim8, TIM_CHANNEL_1);
	HAL_TIMEx_PWMN_Start(&htim8, TIM_CHANNEL_1);
	HAL_TIM_PWM_Start(&htim8, TIM_CHANNEL_2);
	HAL_TIMEx_PWMN_Start(&htim8, TIM_CHANNEL_2);
	HAL_TIM_PWM_Start(&htim8, TIM_CHANNEL_3);
	HAL_TIMEx_PWMN_Start(&htim8, TIM_CHANNEL_3);
	HAL_TIM_OC_Start(&htim8, TIM_CHANNEL_4);
	HAL_TIM_Base_Start_IT(&htim8);
#endif
	//	ADC
	/* Peripheral DMA init*/
#if 1
	HAL_ADC_Start_IT(&hadc1);
	HAL_ADC_Start_IT(&hadc2);
	#ifdef ADC_USE_DMA
	/* Invalidate D-cache before reception */
	/* Make sure the address is 32-byte aligned and add 32-bytes to length, in case it overlaps cacheline */
	//SCB_InvalidateDCache_by_Addr((uint32_t*)(((uint32_t)adc3Result) & ~(uint32_t)0x1F), ADC3_CHANNEL_NUM+32);
	HAL_ADC_Start_DMA(&hadc3,
				(uint32_t *)adc3Result, ADC3_CHANNEL_NUM);
	//                        (uint32_t *)aADCxConvertedValues, ADCCONVERTEDVALUES_BUFFER_SIZE);
	#else
	HAL_ADC_Start_IT(&hadc3);
	#endif
	//	Encoder
	HAL_TIM_Encoder_Start(&htim2, TIM_CHANNEL_1);
	HAL_TIM_Encoder_Start(&htim2, TIM_CHANNEL_2);
#endif

	//	CAN
	#ifdef SERVO_FUNC_USE
	//Can_config(&hfdcan1, 1);
	#endif
	FDCAN1_Setting();
	//FDCAN2_Setting();
	//Hall
	//HAL_TIMEx_HallSensor_Start(&htim1); //pjg++181105
	//htim1.Instance->SMCR |= TIM_TS_TI1F_ED; //pjg++181107
	/* Enable the Hall sensor interface (XOR function of the three inputs) */
	//htim1.Instance->CR2 |= TIM_CR2_TI1S; //pjg++181107
	//HAL_TIM_Encoder_Start(&htim1, TIM_CHANNEL_ALL); //pjg++181107
  /* USER CODE END 2 */

  /* Infinite loop */
  while (1)
  {

    /* USER CODE BEGIN 3 */
	//nRunLed++;
	//if (nRunLed > 3000) {
		//HAL_GPIO_TogglePin(GPIOC, RUN_LED_Pin);
		//HAL_FDCAN_AddMessageToTxFifoQ(&hfdcan1, &TxHeader[0], TxData2);
		//HAL_Delay(100);
	//	nRunLed = 0;

	//}
    //HAL_IWDG_Refresh(&hiwdg);
  }
  /* USER CODE END 3 */
}

void SystemClock_Config(void)
{
  RCC_OscInitTypeDef RCC_OscInitStruct = {0};
  RCC_ClkInitTypeDef RCC_ClkInitStruct = {0};
  RCC_PeriphCLKInitTypeDef PeriphClkInitStruct = {0};

  /** Supply configuration update enable
  */
  HAL_PWREx_ConfigSupply(PWR_LDO_SUPPLY);
  /** Configure the main internal regulator output voltage
  */
  __HAL_PWR_VOLTAGESCALING_CONFIG(PWR_REGULATOR_VOLTAGE_SCALE1);

  while(!__HAL_PWR_GET_FLAG(PWR_FLAG_VOSRDY)) {}
  /** Macro to configure the PLL clock source
  */
  __HAL_RCC_PLL_PLLSOURCE_CONFIG(RCC_PLLSOURCE_HSE);
  /** Initializes the CPU, AHB and APB busses clocks
  */
  RCC_OscInitStruct.OscillatorType = RCC_OSCILLATORTYPE_HSE;
  RCC_OscInitStruct.HSEState = RCC_HSE_ON;
  RCC_OscInitStruct.PLL.PLLState = RCC_PLL_ON;
  RCC_OscInitStruct.PLL.PLLSource = RCC_PLLSOURCE_HSE;
  RCC_OscInitStruct.PLL.PLLM = 2;
  RCC_OscInitStruct.PLL.PLLN = 168;
  RCC_OscInitStruct.PLL.PLLP = 2;
  RCC_OscInitStruct.PLL.PLLQ = 4;
  RCC_OscInitStruct.PLL.PLLR = 4;
  RCC_OscInitStruct.PLL.PLLRGE = RCC_PLL1VCIRANGE_2;
  RCC_OscInitStruct.PLL.PLLVCOSEL = RCC_PLL1VCOWIDE;
  RCC_OscInitStruct.PLL.PLLFRACN = 0;
  if (HAL_RCC_OscConfig(&RCC_OscInitStruct) != HAL_OK)
  {
    Error_Handler();
  }
  /** Initializes the CPU, AHB and APB busses clocks
  */
  RCC_ClkInitStruct.ClockType = RCC_CLOCKTYPE_HCLK|RCC_CLOCKTYPE_SYSCLK
                              |RCC_CLOCKTYPE_PCLK1|RCC_CLOCKTYPE_PCLK2
                              |RCC_CLOCKTYPE_D3PCLK1|RCC_CLOCKTYPE_D1PCLK1;
  RCC_ClkInitStruct.SYSCLKSource = RCC_SYSCLKSOURCE_PLLCLK;
  RCC_ClkInitStruct.SYSCLKDivider = RCC_SYSCLK_DIV2;
  RCC_ClkInitStruct.AHBCLKDivider = RCC_HCLK_DIV1;
  RCC_ClkInitStruct.APB3CLKDivider = RCC_APB3_DIV2;
  RCC_ClkInitStruct.APB1CLKDivider = RCC_APB1_DIV2;
  RCC_ClkInitStruct.APB2CLKDivider = RCC_APB2_DIV2;
  RCC_ClkInitStruct.APB4CLKDivider = RCC_APB4_DIV2;

  if (HAL_RCC_ClockConfig(&RCC_ClkInitStruct, FLASH_LATENCY_2) != HAL_OK)
  {
    Error_Handler();
  }
  PeriphClkInitStruct.PeriphClockSelection = RCC_PERIPHCLK_USART3|RCC_PERIPHCLK_FDCAN
                              |RCC_PERIPHCLK_USART1|RCC_PERIPHCLK_ADC;
  PeriphClkInitStruct.PLL2.PLL2M = 1;
  PeriphClkInitStruct.PLL2.PLL2N = 32;
  PeriphClkInitStruct.PLL2.PLL2P = 4;
  PeriphClkInitStruct.PLL2.PLL2Q = 32;
  PeriphClkInitStruct.PLL2.PLL2R = 2;
  PeriphClkInitStruct.PLL2.PLL2RGE = RCC_PLL2VCIRANGE_3;
  PeriphClkInitStruct.PLL2.PLL2VCOSEL = RCC_PLL2VCOWIDE;
  PeriphClkInitStruct.PLL2.PLL2FRACN = 0;
  PeriphClkInitStruct.PLL3.PLL3M = 8;
  PeriphClkInitStruct.PLL3.PLL3N = 168;
  PeriphClkInitStruct.PLL3.PLL3P = 2;
  PeriphClkInitStruct.PLL3.PLL3Q = 2;
  PeriphClkInitStruct.PLL3.PLL3R = 2;
  PeriphClkInitStruct.PLL3.PLL3RGE = RCC_PLL3VCIRANGE_0;
  PeriphClkInitStruct.PLL3.PLL3VCOSEL = RCC_PLL3VCOMEDIUM;
  PeriphClkInitStruct.PLL3.PLL3FRACN = 0;
  PeriphClkInitStruct.FdcanClockSelection = RCC_FDCANCLKSOURCE_PLL2;
  PeriphClkInitStruct.Usart234578ClockSelection = RCC_USART234578CLKSOURCE_D2PCLK1;
  PeriphClkInitStruct.Usart16ClockSelection = RCC_USART16CLKSOURCE_D2PCLK2;
  PeriphClkInitStruct.AdcClockSelection = RCC_ADCCLKSOURCE_PLL3;
  if (HAL_RCCEx_PeriphCLKConfig(&PeriphClkInitStruct) != HAL_OK)
  {
    Error_Handler();
  }
}

static void MX_ADC1_Init(void)
{

  ADC_MultiModeTypeDef multimode = {0};
  ADC_ChannelConfTypeDef sConfig = {0};

  /** Common config
  */
  hadc1.Instance = ADC1;
  hadc1.Init.ClockPrescaler = ADC_CLOCK_ASYNC_DIV8;
  hadc1.Init.Resolution = ADC_RESOLUTION_12B;
  hadc1.Init.ScanConvMode = ADC_SCAN_DISABLE;
  hadc1.Init.EOCSelection = ADC_EOC_SINGLE_CONV;
  hadc1.Init.LowPowerAutoWait = DISABLE;
  hadc1.Init.ContinuousConvMode = DISABLE;
  hadc1.Init.NbrOfConversion = 1;
  hadc1.Init.DiscontinuousConvMode = DISABLE;
  hadc1.Init.ExternalTrigConv = ADC_EXTERNALTRIG_T8_TRGO;
  hadc1.Init.ExternalTrigConvEdge = ADC_EXTERNALTRIGCONVEDGE_FALLING;
  hadc1.Init.ConversionDataManagement = ADC_CONVERSIONDATA_DR;
  hadc1.Init.Overrun = ADC_OVR_DATA_PRESERVED;
  hadc1.Init.LeftBitShift = ADC_LEFTBITSHIFT_NONE;
  hadc1.Init.OversamplingMode = DISABLE;
  if (HAL_ADC_Init(&hadc1) != HAL_OK)
  {
    Error_Handler();
  }
  /** Configure the ADC multi-mode
  */
  multimode.Mode = ADC_MODE_INDEPENDENT;
  if (HAL_ADCEx_MultiModeConfigChannel(&hadc1, &multimode) != HAL_OK)
  {
    Error_Handler();
  }
  /** Configure Regular Channel
  */
  sConfig.Channel = ADC_CHANNEL_10;
  sConfig.Rank = ADC_REGULAR_RANK_1;
  sConfig.SamplingTime = ADC_SAMPLETIME_16CYCLES_5;
  sConfig.SingleDiff = ADC_SINGLE_ENDED;
  sConfig.OffsetNumber = ADC_OFFSET_NONE;
  sConfig.Offset = 0;
  if (HAL_ADC_ConfigChannel(&hadc1, &sConfig) != HAL_OK)
  {
    Error_Handler();
  }

}

static void MX_ADC2_Init(void)
{

  ADC_ChannelConfTypeDef sConfig = {0};

  /** Common config
  */
  hadc2.Instance = ADC2;
  hadc2.Init.ClockPrescaler = ADC_CLOCK_ASYNC_DIV8;
  hadc2.Init.Resolution = ADC_RESOLUTION_12B;
  hadc2.Init.ScanConvMode = ADC_SCAN_DISABLE;
  hadc2.Init.EOCSelection = ADC_EOC_SINGLE_CONV;
  hadc2.Init.LowPowerAutoWait = DISABLE;
  hadc2.Init.ContinuousConvMode = DISABLE;
  hadc2.Init.NbrOfConversion = 1;
  hadc2.Init.DiscontinuousConvMode = DISABLE;
  hadc2.Init.ExternalTrigConv = ADC_EXTERNALTRIG_T8_TRGO;
  hadc2.Init.ExternalTrigConvEdge = ADC_EXTERNALTRIGCONVEDGE_FALLING;
  hadc2.Init.ConversionDataManagement = ADC_CONVERSIONDATA_DR;
  hadc2.Init.Overrun = ADC_OVR_DATA_PRESERVED;
  hadc2.Init.LeftBitShift = ADC_LEFTBITSHIFT_NONE;
  hadc2.Init.OversamplingMode = DISABLE;
  if (HAL_ADC_Init(&hadc2) != HAL_OK)
  {
    Error_Handler();
  }
  /** Configure Regular Channel
  */
  sConfig.Channel = ADC_CHANNEL_11;
  sConfig.Rank = ADC_REGULAR_RANK_1;
  sConfig.SamplingTime = ADC_SAMPLETIME_16CYCLES_5;
  sConfig.SingleDiff = ADC_SINGLE_ENDED;
  sConfig.OffsetNumber = ADC_OFFSET_NONE;
  sConfig.Offset = 0;
  if (HAL_ADC_ConfigChannel(&hadc2, &sConfig) != HAL_OK)
  {
    Error_Handler();
  }

}

static void MX_ADC3_Init(void)
{

  ADC_ChannelConfTypeDef sConfig = {0};

  /** Common config
  */
  hadc3.Instance = ADC3;
  hadc3.Init.ClockPrescaler = ADC_CLOCK_ASYNC_DIV8;
  hadc3.Init.Resolution = ADC_RESOLUTION_12B;
  hadc3.Init.ScanConvMode = ADC_SCAN_ENABLE;
  hadc3.Init.EOCSelection = ADC_EOC_SINGLE_CONV;
  hadc3.Init.LowPowerAutoWait = DISABLE;
  hadc3.Init.ContinuousConvMode = DISABLE;
  hadc3.Init.NbrOfConversion = 3;
  hadc3.Init.DiscontinuousConvMode = DISABLE;
  hadc3.Init.ExternalTrigConv = ADC_EXTERNALTRIG_T8_TRGO;
  hadc3.Init.ExternalTrigConvEdge = ADC_EXTERNALTRIGCONVEDGE_FALLING;
  hadc3.Init.ConversionDataManagement = ADC_CONVERSIONDATA_DMA_CIRCULAR;
  hadc3.Init.Overrun = ADC_OVR_DATA_PRESERVED;
  hadc3.Init.LeftBitShift = ADC_LEFTBITSHIFT_NONE;
  hadc3.Init.OversamplingMode = DISABLE;
  if (HAL_ADC_Init(&hadc3) != HAL_OK)
  {
    Error_Handler();
  }
  /** Configure Regular Channel
  */
  sConfig.Channel = ADC_CHANNEL_0;
  sConfig.Rank = ADC_REGULAR_RANK_1;
  sConfig.SamplingTime = ADC_SAMPLETIME_16CYCLES_5;
  sConfig.SingleDiff = ADC_SINGLE_ENDED;
  sConfig.OffsetNumber = ADC_OFFSET_NONE;
  sConfig.Offset = 0;
  if (HAL_ADC_ConfigChannel(&hadc3, &sConfig) != HAL_OK)
  {
    Error_Handler();
  }
  /** Configure Regular Channel
  */
  sConfig.Channel = ADC_CHANNEL_1;
  sConfig.Rank = ADC_REGULAR_RANK_2;
  sConfig.SamplingTime = ADC_SAMPLETIME_2CYCLES_5;
  if (HAL_ADC_ConfigChannel(&hadc3, &sConfig) != HAL_OK)
  {
    Error_Handler();
  }
  /** Configure Regular Channel
  */
  sConfig.Channel = ADC_CHANNEL_TEMPSENSOR;
  sConfig.Rank = ADC_REGULAR_RANK_3;
  sConfig.SamplingTime = ADC_SAMPLETIME_16CYCLES_5;
  if (HAL_ADC_ConfigChannel(&hadc3, &sConfig) != HAL_OK)
  {
    Error_Handler();
  }

}

static void MX_FDCAN1_Init(void)
{

  hfdcan1.Instance = FDCAN1;
  hfdcan1.Init.FrameFormat = FDCAN_FRAME_CLASSIC;
  hfdcan1.Init.Mode = FDCAN_MODE_NORMAL;
  hfdcan1.Init.AutoRetransmission = DISABLE;
  hfdcan1.Init.TransmitPause = DISABLE;
  hfdcan1.Init.ProtocolException = DISABLE;
  hfdcan1.Init.NominalPrescaler = 1;
  hfdcan1.Init.NominalSyncJumpWidth = 8;
  hfdcan1.Init.NominalTimeSeg1 = 3;
  hfdcan1.Init.NominalTimeSeg2 = 4;
  hfdcan1.Init.DataPrescaler = 1;
  hfdcan1.Init.DataSyncJumpWidth = 8;
  hfdcan1.Init.DataTimeSeg1 = 3;
  hfdcan1.Init.DataTimeSeg2 = 4;
  hfdcan1.Init.MessageRAMOffset = 0;
  hfdcan1.Init.StdFiltersNbr = 1;
  hfdcan1.Init.ExtFiltersNbr = 0;
  hfdcan1.Init.RxFifo0ElmtsNbr = 1;
  hfdcan1.Init.RxFifo0ElmtSize = FDCAN_DATA_BYTES_8;
  hfdcan1.Init.RxFifo1ElmtsNbr = 0;
  hfdcan1.Init.RxFifo1ElmtSize = FDCAN_DATA_BYTES_8;
  hfdcan1.Init.RxBuffersNbr = 0;
  hfdcan1.Init.RxBufferSize = FDCAN_DATA_BYTES_8;
  hfdcan1.Init.TxEventsNbr = 0;
  hfdcan1.Init.TxBuffersNbr = 0;
  hfdcan1.Init.TxFifoQueueElmtsNbr = 4;
  hfdcan1.Init.TxFifoQueueMode = FDCAN_TX_FIFO_OPERATION;
  hfdcan1.Init.TxElmtSize = FDCAN_DATA_BYTES_8;
  if (HAL_FDCAN_Init(&hfdcan1) != HAL_OK)
  {
    Error_Handler();
  }

}

static void MX_FDCAN2_Init(void)
{

  hfdcan2.Instance = FDCAN2;
  hfdcan2.Init.FrameFormat = FDCAN_FRAME_FD_BRS;
  hfdcan2.Init.Mode = FDCAN_MODE_NORMAL;
  hfdcan2.Init.AutoRetransmission = DISABLE;
  hfdcan2.Init.TransmitPause = DISABLE;
  hfdcan2.Init.ProtocolException = DISABLE;
  hfdcan2.Init.NominalPrescaler = 1;
  hfdcan2.Init.NominalSyncJumpWidth = 8;
  hfdcan2.Init.NominalTimeSeg1 = 39;
  hfdcan2.Init.NominalTimeSeg2 = 8;
  hfdcan2.Init.DataPrescaler = 1;
  hfdcan2.Init.DataSyncJumpWidth = 4;
  hfdcan2.Init.DataTimeSeg1 = 4;
  hfdcan2.Init.DataTimeSeg2 = 3;
  hfdcan2.Init.MessageRAMOffset = 0;
  hfdcan2.Init.StdFiltersNbr = 0;
  hfdcan2.Init.ExtFiltersNbr = 0;
  hfdcan2.Init.RxFifo0ElmtsNbr = 0;
  hfdcan2.Init.RxFifo0ElmtSize = FDCAN_DATA_BYTES_64;
  hfdcan2.Init.RxFifo1ElmtsNbr = 0;
  hfdcan2.Init.RxFifo1ElmtSize = FDCAN_DATA_BYTES_64;
  hfdcan2.Init.RxBuffersNbr = 0;
  hfdcan2.Init.RxBufferSize = FDCAN_DATA_BYTES_64;
  hfdcan2.Init.TxEventsNbr = 0;
  hfdcan2.Init.TxBuffersNbr = 0;
  hfdcan2.Init.TxFifoQueueElmtsNbr = 0;
  hfdcan2.Init.TxFifoQueueMode = FDCAN_TX_FIFO_OPERATION;
  hfdcan2.Init.TxElmtSize = FDCAN_DATA_BYTES_64;
  if (HAL_FDCAN_Init(&hfdcan2) != HAL_OK)
  {
    Error_Handler();
  }

}

static void MX_TIM2_Init(void)
{

  TIM_Encoder_InitTypeDef sConfig = {0};
  TIM_MasterConfigTypeDef sMasterConfig = {0};

  htim2.Instance = TIM2;
  htim2.Init.Prescaler = 0;
  htim2.Init.CounterMode = TIM_COUNTERMODE_UP;
  htim2.Init.Period = 4294967295;
  htim2.Init.ClockDivision = TIM_CLOCKDIVISION_DIV1;
  htim2.Init.AutoReloadPreload = TIM_AUTORELOAD_PRELOAD_DISABLE;
  sConfig.EncoderMode = TIM_ENCODERMODE_TI12;
  sConfig.IC1Polarity = TIM_ICPOLARITY_RISING;
  sConfig.IC1Selection = TIM_ICSELECTION_DIRECTTI;
  sConfig.IC1Prescaler = TIM_ICPSC_DIV1;
  sConfig.IC1Filter = 0;
  sConfig.IC2Polarity = TIM_ICPOLARITY_RISING;
  sConfig.IC2Selection = TIM_ICSELECTION_DIRECTTI;
  sConfig.IC2Prescaler = TIM_ICPSC_DIV1;
  sConfig.IC2Filter = 0;
  if (HAL_TIM_Encoder_Init(&htim2, &sConfig) != HAL_OK)
  {
    Error_Handler();
  }
  sMasterConfig.MasterOutputTrigger = TIM_TRGO_RESET;
  sMasterConfig.MasterSlaveMode = TIM_MASTERSLAVEMODE_DISABLE;
  if (HAL_TIMEx_MasterConfigSynchronization(&htim2, &sMasterConfig) != HAL_OK)
  {
    Error_Handler();
  }

}

static void MX_TIM8_Init(void)
{

  /* USER CODE BEGIN TIM8_Init 0 */
  #define OC_TIME_CNT				4158

  /* USER CODE END TIM8_Init 0 */

  TIM_ClockConfigTypeDef sClockSourceConfig = {0};
  TIM_MasterConfigTypeDef sMasterConfig = {0};
  TIM_OC_InitTypeDef sConfigOC = {0};
  TIM_BreakDeadTimeConfigTypeDef sBreakDeadTimeConfig = {0};

  htim8.Instance = TIM8;
  htim8.Init.Prescaler = 0;
  htim8.Init.CounterMode = TIM_COUNTERMODE_CENTERALIGNED1;
  htim8.Init.Period = 4200;
  htim8.Init.ClockDivision = TIM_CLOCKDIVISION_DIV1;
  htim8.Init.RepetitionCounter = 0;
  htim8.Init.AutoReloadPreload = TIM_AUTORELOAD_PRELOAD_DISABLE;
  if (HAL_TIM_Base_Init(&htim8) != HAL_OK)
  {
    Error_Handler();
  }
  sClockSourceConfig.ClockSource = TIM_CLOCKSOURCE_INTERNAL;
  if (HAL_TIM_ConfigClockSource(&htim8, &sClockSourceConfig) != HAL_OK)
  {
    Error_Handler();
  }
  if (HAL_TIM_PWM_Init(&htim8) != HAL_OK)
  {
    Error_Handler();
  }
  if (HAL_TIM_OC_Init(&htim8) != HAL_OK)
  {
    Error_Handler();
  }
  sMasterConfig.MasterOutputTrigger = TIM_TRGO_OC4REF;
  sMasterConfig.MasterOutputTrigger2 = TIM_TRGO2_OC4REF;
  sMasterConfig.MasterSlaveMode = TIM_MASTERSLAVEMODE_DISABLE;
  if (HAL_TIMEx_MasterConfigSynchronization(&htim8, &sMasterConfig) != HAL_OK)
  {
    Error_Handler();
  }
  sConfigOC.OCMode = TIM_OCMODE_PWM2;
  sConfigOC.Pulse = 4200;
  sConfigOC.OCPolarity = TIM_OCPOLARITY_HIGH;
  sConfigOC.OCNPolarity = TIM_OCNPOLARITY_HIGH;
  sConfigOC.OCFastMode = TIM_OCFAST_DISABLE;
  sConfigOC.OCIdleState = TIM_OCIDLESTATE_RESET;
  sConfigOC.OCNIdleState = TIM_OCNIDLESTATE_RESET;
  if (HAL_TIM_PWM_ConfigChannel(&htim8, &sConfigOC, TIM_CHANNEL_1) != HAL_OK)
  {
    Error_Handler();
  }
  if (HAL_TIM_PWM_ConfigChannel(&htim8, &sConfigOC, TIM_CHANNEL_2) != HAL_OK)
  {
    Error_Handler();
  }
  if (HAL_TIM_PWM_ConfigChannel(&htim8, &sConfigOC, TIM_CHANNEL_3) != HAL_OK)
  {
    Error_Handler();
  }
  sConfigOC.OCMode = TIM_OCMODE_TOGGLE;
  sConfigOC.Pulse = 4158;
  if (HAL_TIM_OC_ConfigChannel(&htim8, &sConfigOC, TIM_CHANNEL_4) != HAL_OK)
  {
    Error_Handler();
  }
  sBreakDeadTimeConfig.OffStateRunMode = TIM_OSSR_DISABLE;
  sBreakDeadTimeConfig.OffStateIDLEMode = TIM_OSSI_DISABLE;
  sBreakDeadTimeConfig.LockLevel = TIM_LOCKLEVEL_OFF;
  sBreakDeadTimeConfig.DeadTime = 84;
  sBreakDeadTimeConfig.BreakState = TIM_BREAK_DISABLE;
  sBreakDeadTimeConfig.BreakPolarity = TIM_BREAKPOLARITY_HIGH;
  sBreakDeadTimeConfig.BreakFilter = 0;
  sBreakDeadTimeConfig.Break2State = TIM_BREAK2_DISABLE;
  sBreakDeadTimeConfig.Break2Polarity = TIM_BREAK2POLARITY_HIGH;
  sBreakDeadTimeConfig.Break2Filter = 0;
  sBreakDeadTimeConfig.AutomaticOutput = TIM_AUTOMATICOUTPUT_DISABLE;
  if (HAL_TIMEx_ConfigBreakDeadTime(&htim8, &sBreakDeadTimeConfig) != HAL_OK)
  {
    Error_Handler();
  }
  HAL_TIM_MspPostInit(&htim8);

}

static void MX_USART1_UART_Init(void)
{

  huart1.Instance = USART1;
  huart1.Init.BaudRate = 115200;
  huart1.Init.WordLength = UART_WORDLENGTH_8B;
  huart1.Init.StopBits = UART_STOPBITS_1;
  huart1.Init.Parity = UART_PARITY_NONE;
  huart1.Init.Mode = UART_MODE_TX_RX;
  huart1.Init.HwFlowCtl = UART_HWCONTROL_NONE;
  huart1.Init.OverSampling = UART_OVERSAMPLING_16;
  huart1.Init.OneBitSampling = UART_ONE_BIT_SAMPLE_DISABLE;
  huart1.Init.ClockPrescaler = UART_PRESCALER_DIV1;
  huart1.AdvancedInit.AdvFeatureInit = UART_ADVFEATURE_NO_INIT;
  if (HAL_UART_Init(&huart1) != HAL_OK)
  {
    Error_Handler();
  }
  if (HAL_UARTEx_SetTxFifoThreshold(&huart1, UART_TXFIFO_THRESHOLD_1_8) != HAL_OK)
  {
    Error_Handler();
  }
  if (HAL_UARTEx_SetRxFifoThreshold(&huart1, UART_RXFIFO_THRESHOLD_1_8) != HAL_OK)
  {
    Error_Handler();
  }
  if (HAL_UARTEx_DisableFifoMode(&huart1) != HAL_OK)
  {
    Error_Handler();
  }

}

static void MX_USART3_UART_Init(void)
{

  huart3.Instance = USART3;
  huart3.Init.BaudRate = 115200;
  huart3.Init.WordLength = UART_WORDLENGTH_8B;
  huart3.Init.StopBits = UART_STOPBITS_1;
  huart3.Init.Parity = UART_PARITY_NONE;
  huart3.Init.Mode = UART_MODE_TX_RX;
  huart3.Init.HwFlowCtl = UART_HWCONTROL_NONE;
  huart3.Init.OverSampling = UART_OVERSAMPLING_16;
  huart3.Init.OneBitSampling = UART_ONE_BIT_SAMPLE_DISABLE;
  huart3.Init.ClockPrescaler = UART_PRESCALER_DIV1;
  huart3.AdvancedInit.AdvFeatureInit = UART_ADVFEATURE_NO_INIT;
  if (HAL_UART_Init(&huart3) != HAL_OK)
  {
    Error_Handler();
  }
  if (HAL_UARTEx_SetTxFifoThreshold(&huart3, UART_TXFIFO_THRESHOLD_1_8) != HAL_OK)
  {
    Error_Handler();
  }
  if (HAL_UARTEx_SetRxFifoThreshold(&huart3, UART_RXFIFO_THRESHOLD_1_8) != HAL_OK)
  {
    Error_Handler();
  }
  if (HAL_UARTEx_DisableFifoMode(&huart3) != HAL_OK)
  {
    Error_Handler();
  }

}

static void MX_DMA_Init(void)
{

  /* DMA controller clock enable */
  __HAL_RCC_DMA1_CLK_ENABLE();

  /* DMA interrupt init */
  /* DMA1_Stream0_IRQn interrupt configuration */
  HAL_NVIC_SetPriority(DMA1_Stream0_IRQn, 0, 0);
  HAL_NVIC_EnableIRQ(DMA1_Stream0_IRQn);
  /* DMA1_Stream1_IRQn interrupt configuration */
  HAL_NVIC_SetPriority(DMA1_Stream1_IRQn, 2, 0);
  HAL_NVIC_EnableIRQ(DMA1_Stream1_IRQn);
  /* DMA1_Stream2_IRQn interrupt configuration */
  HAL_NVIC_SetPriority(DMA1_Stream2_IRQn, 2, 0);
  HAL_NVIC_EnableIRQ(DMA1_Stream2_IRQn);

}

static void MX_GPIO_Init(void)
{
  GPIO_InitTypeDef GPIO_InitStruct = {0};

  /* GPIO Ports Clock Enable */
  __HAL_RCC_GPIOC_CLK_ENABLE();
  __HAL_RCC_GPIOH_CLK_ENABLE();
  __HAL_RCC_GPIOA_CLK_ENABLE();
  __HAL_RCC_GPIOB_CLK_ENABLE();
  __HAL_RCC_GPIOE_CLK_ENABLE();
  __HAL_RCC_GPIOD_CLK_ENABLE();

  /*Configure GPIO pin Output Level */
  HAL_GPIO_WritePin(GPIOC, RUN_LED_Pin|ERROR_LED_Pin|STATUS_LED_Pin|VOLTAGE_CTRL_Pin
                          |STATUS2_LED_Pin, GPIO_PIN_RESET);

  /*Configure GPIO pin Output Level */
  HAL_GPIO_WritePin(BRAKE_CTRL_GPIO_Port, BRAKE_CTRL_Pin, GPIO_PIN_RESET);

  /*Configure GPIO pins : RUN_LED_Pin ERROR_LED_Pin STATUS_LED_Pin STATUS2_LED_Pin */
  GPIO_InitStruct.Pin = RUN_LED_Pin|ERROR_LED_Pin|STATUS_LED_Pin|STATUS2_LED_Pin;
  GPIO_InitStruct.Mode = GPIO_MODE_OUTPUT_PP;
  GPIO_InitStruct.Pull = GPIO_NOPULL;
  GPIO_InitStruct.Speed = GPIO_SPEED_FREQ_LOW;
  HAL_GPIO_Init(GPIOC, &GPIO_InitStruct);

  /*Configure GPIO pin : BRAKE_CTRL_Pin */
  GPIO_InitStruct.Pin = BRAKE_CTRL_Pin;
  GPIO_InitStruct.Mode = GPIO_MODE_OUTPUT_PP;
  GPIO_InitStruct.Pull = GPIO_PULLDOWN;
  GPIO_InitStruct.Speed = GPIO_SPEED_FREQ_VERY_HIGH;
  HAL_GPIO_Init(BRAKE_CTRL_GPIO_Port, &GPIO_InitStruct);

  /*Configure GPIO pin : VOLTAGE_CTRL_Pin */
  GPIO_InitStruct.Pin = VOLTAGE_CTRL_Pin;
  GPIO_InitStruct.Mode = GPIO_MODE_OUTPUT_PP;
  GPIO_InitStruct.Pull = GPIO_PULLDOWN;
  GPIO_InitStruct.Speed = GPIO_SPEED_FREQ_VERY_HIGH;
  HAL_GPIO_Init(VOLTAGE_CTRL_GPIO_Port, &GPIO_InitStruct);

  /*Configure GPIO pins : HALL1_Pin HALL2_Pin HALL3_Pin */
  GPIO_InitStruct.Pin = HALL1_Pin|HALL2_Pin|HALL3_Pin;
  GPIO_InitStruct.Mode = GPIO_MODE_INPUT;
  GPIO_InitStruct.Pull = GPIO_NOPULL;
  HAL_GPIO_Init(GPIOE, &GPIO_InitStruct);

  /*Configure GPIO pins : HALL1_GPIO_Pin HALL2_GPIO_Pin HALL3_GPIO_Pin */
  GPIO_InitStruct.Pin = HALL1_GPIO_Pin|HALL2_GPIO_Pin|HALL3_GPIO_Pin;
  GPIO_InitStruct.Mode = GPIO_MODE_INPUT;
  GPIO_InitStruct.Pull = GPIO_NOPULL;
  HAL_GPIO_Init(GPIOD, &GPIO_InitStruct);

  /*Configure GPIO pin : ADC_TRIGGER_Pin */
  GPIO_InitStruct.Pin = ADC_TRIGGER_Pin;
  GPIO_InitStruct.Mode = GPIO_MODE_IT_RISING;
  GPIO_InitStruct.Pull = GPIO_PULLDOWN;
  HAL_GPIO_Init(ADC_TRIGGER_GPIO_Port, &GPIO_InitStruct);

  /*Configure GPIO pins : NEGATIVE_SW_Pin POSITIVE_SW_Pin HOME_SW_Pin */
  GPIO_InitStruct.Pin = NEGATIVE_SW_Pin|POSITIVE_SW_Pin|HOME_SW_Pin;
  GPIO_InitStruct.Mode = GPIO_MODE_INPUT;
  GPIO_InitStruct.Pull = GPIO_PULLDOWN;
  HAL_GPIO_Init(GPIOB, &GPIO_InitStruct);

  /* EXTI interrupt init*/
  HAL_NVIC_SetPriority(EXTI2_IRQn, 0, 0);
  HAL_NVIC_EnableIRQ(EXTI2_IRQn);

}

void Error_Handler(void)
{
}

/************************ (C) COPYRIGHT STMicroelectronics *****END OF FILE****/
